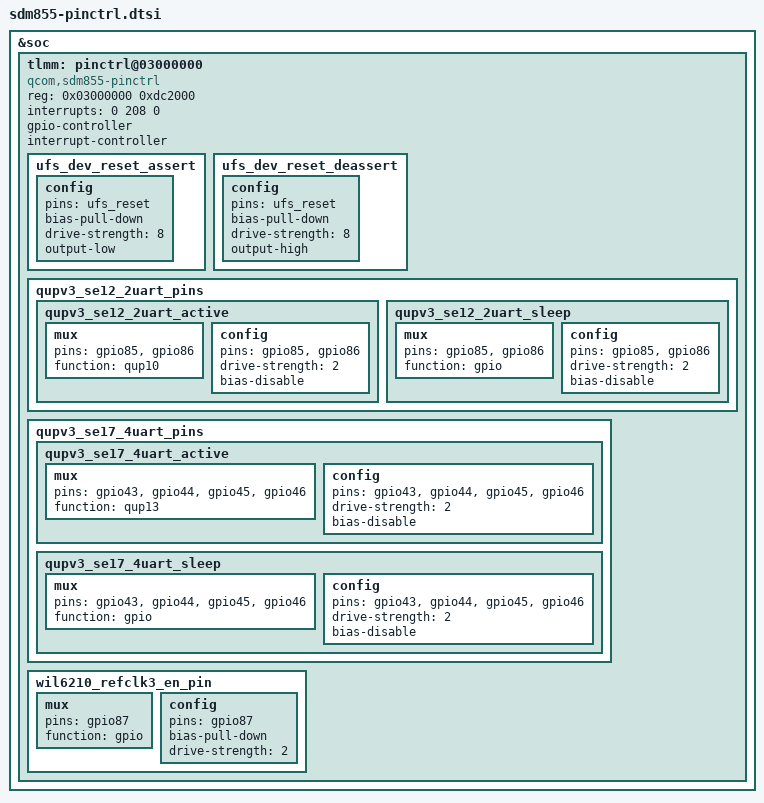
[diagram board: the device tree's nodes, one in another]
/* Copyright (c) 2017, The Linux Foundation. All rights reserved.
 *
 * This program is free software; you can redistribute it and/or modify
 * it under the terms of the GNU General Public License version 2 and
 * only version 2 as published by the Free Software Foundation.
 *
 * This program is distributed in the hope that it will be useful,
 * but WITHOUT ANY WARRANTY; without even the implied warranty of
 * MERCHANTABILITY or FITNESS FOR A PARTICULAR PURPOSE.  See the
 * GNU General Public License for more details.
 */

&soc {
	tlmm: pinctrl@03000000 {
		compatible = "qcom,sdm855-pinctrl";
		reg = <0x03000000 0xdc2000>;
		interrupts = <0 208 0>;
		gpio-controller;
		#gpio-cells = <2>;
		interrupt-controller;
		#interrupt-cells = <2>;

		ufs_dev_reset_assert: ufs_dev_reset_assert {
			config {
				pins = "ufs_reset";
				bias-pull-down;		/* default: pull down */
				/*
				 * UFS_RESET driver strengths are having
				 * different values/steps compared to typical
				 * GPIO drive strengths.
				 *
				 * Following table clarifies:
				 *
				 * HDRV value | UFS_RESET | Typical GPIO
				 *   (dec)    |   (mA)    |    (mA)
				 *     0      |   0.8     |    2
				 *     1      |   1.55    |    4
				 *     2      |   2.35    |    6
				 *     3      |   3.1     |    8
				 *     4      |   3.9     |    10
				 *     5      |   4.65    |    12
				 *     6      |   5.4     |    14
				 *     7      |   6.15    |    16
				 *
				 * POR value for UFS_RESET HDRV is 3 which means
				 * 3.1mA and we want to use that. Hence just
				 * specify 8mA to "drive-strength" binding and
				 * that should result into writing 3 to HDRV
				 * field.
				 */
				drive-strength = <8>;	/* default: 3.1 mA */
				output-low; /* active low reset */
			};
		};

		ufs_dev_reset_deassert: ufs_dev_reset_deassert {
			config {
				pins = "ufs_reset";
				bias-pull-down;		/* default: pull down */
				/*
				 * default: 3.1 mA
				 * check comments under ufs_dev_reset_assert
				 */
				drive-strength = <8>;
				output-high; /* active low reset */
			};
		};

		qupv3_se12_2uart_pins: qupv3_se12_2uart_pins {
			qupv3_se12_2uart_active: qupv3_se12_2uart_active {
				mux {
					pins = "gpio85", "gpio86";
					function = "qup10";
				};

				config {
					pins = "gpio85", "gpio86";
					drive-strength = <2>;
					bias-disable;
				};
			};

			qupv3_se12_2uart_sleep: qupv3_se12_2uart_sleep {
				mux {
					pins = "gpio85", "gpio86";
					function = "gpio";
				};

				config {
					pins = "gpio85", "gpio86";
					drive-strength = <2>;
					bias-disable;
				};
			};
		};

		qupv3_se17_4uart_pins: qupv3_se17_4uart_pins {
			qupv3_se17_4uart_active: qupv3_se17_4uart_active {
				mux {
					pins = "gpio43", "gpio44", "gpio45",
								"gpio46";
					function = "qup13";
				};

				config {
					pins = "gpio43", "gpio44", "gpio45",
								"gpio46";
					drive-strength = <2>;
					bias-disable;
				};
			};

			qupv3_se17_4uart_sleep: qupv3_se17_4uart_sleep {
				mux {
					pins = "gpio43", "gpio44", "gpio45",
								"gpio46";
					function = "gpio";
				};

				config {
					pins = "gpio43", "gpio44", "gpio45",
								"gpio46";
					drive-strength = <2>;
					bias-disable;
				};
			};
		};

		wil6210_refclk3_en_pin: wil6210_refclk3_en_pin {
			mux {
				pins = "gpio87";
				function = "gpio";
			};

			config {
				pins = "gpio87";
				bias-pull-down;		/* PULL DOWN */
				drive-strength = <2>;	/* 2 MA */
			};
		};
	};
};
